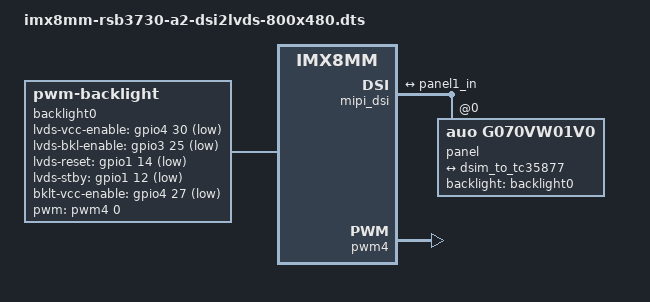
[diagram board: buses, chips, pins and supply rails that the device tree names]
/*
 * Copyright 2018 NXP
 *
 * This program is free software; you can redistribute it and/or
 * modify it under the terms of the GNU General Public License
 * as published by the Free Software Foundation; either version 2
 * of the License, or (at your option) any later version.
 *
 * This program is distributed in the hope that it will be useful,
 * but WITHOUT ANY WARRANTY; without even the implied warranty of
 * MERCHANTABILITY or FITNESS FOR A PARTICULAR PURPOSE.  See the
 * GNU General Public License for more details.
 */

#include "imx8mm-rsb3730-a2.dts"

/ {
	backlight0: backlight@0 {
                compatible = "pwm-backlight";
                pwms = <&pwm4 0 1000000 0>;
                brightness-levels = < 0  1  2  3  4  5  6  7  8  9
                             10 11 12 13 14 15 16 17 18 19
                             20 21 22 23 24 25 26 27 28 29
                             30 31 32 33 34 35 36 37 38 39
                             40 41 42 43 44 45 46 47 48 49
                             50 51 52 53 54 55 56 57 58 59
                             60 61 62 63 64 65 66 67 68 69
                             70 71 72 73 74 75 76 77 78 79
                             80 81 82 83 84 85 86 87 88 89
                             90 91 92 93 94 95 96 97 98 99
                            100>;
                default-brightness-level = <80>;
                default-enable = <0>;
        };
};

&lt9611uxc {
	status = "disabled";
	/delete-node/ ports;
};

&mipi_dsi {
	/delete-node/ port@1;

	panel@0 {
		compatible = "auo,g070vw01v0";
		reg = <0>;
		backlight=<&backlight0>;
		no-wakeup-init;
		panel-init-sequence = [
			29 00 06 3C 01 03 00 02 00
			29 00 06 14 01 02 00 00 00
			29 00 06 64 01 00 00 00 00
			29 00 06 68 01 00 00 00 00
			29 00 06 6C 01 00 00 00 00
			29 00 06 70 01 00 00 00 00
			29 00 06 34 01 1F 00 00 00
			29 00 06 10 02 1F 00 00 00
			29 00 06 04 01 01 00 00 00
			29 00 06 04 02 01 00 00 00
			29 00 06 50 04 20 01 F0 03
			29 00 06 54 04 06 00 32 00
			29 00 06 58 04 20 03 C8 00
			29 00 06 5C 04 04 00 04 00
			29 00 06 60 04 E0 01 14 00
			29 00 06 64 04 01 00 00 00
			29 01 06 A0 04 2D 80 44 00
			29 00 06 A0 04 2D 80 04 00
			29 00 06 04 05 04 00 00 00
			29 00 06 80 04 00 01 02 03
			29 00 06 84 04 04 07 05 08
			29 00 06 88 04 09 0A 0E 0F
			29 00 06 8C 04 0B 0C 0D 10
			29 00 06 90 04 16 17 11 12
			29 00 06 94 04 13 14 15 1B
			29 14 06 98 04 18 19 1A 06
			29 78 06 9C 04 31 00 00 00
		];
		panel-on-sequence = [
			05 78 01 11
			05 78 01 29
		];
		panel-off-sequence = [
			05 05 01 28
			05 78 01 10
		];

		port {
			panel1_in: endpoint {
				remote-endpoint = <&dsim_to_tc35877>;
			};
		};
	};

	port@1 {
		dsim_to_tc35877: endpoint {
			remote-endpoint = <&panel1_in>;
		};
	};
};

&pwm4 {
	status = "okay";
};

&backlight0 {
	pinctrl-names = "default";
	pinctrl-0 = <&pinctrl_bkl>;
	lvds-vcc-enable = <&gpio4 30 1>;
	lvds-bkl-enable = <&gpio3 25 1>;
	lvds-reset=<&gpio1 14 1>;
	lvds-stby=<&gpio1 12 1>;
	bklt-vcc-enable = <&gpio4 27 1>;
	status = "okay";
	lvds-bkl-delay-time = <150>;
	lvds-vcc-delay-time = <20>;
};

&iomuxc {
	pinctrl_bkl: bklgrp {
                fsl,pins = <
                        MX8MM_IOMUXC_SAI3_RXD_GPIO4_IO30	0x10		/* LCD0_VDD_EN */
                        MX8MM_IOMUXC_SAI2_MCLK_GPIO4_IO27	0x19		/* LCD0_BKLT_PWR_EN */
                        MX8MM_IOMUXC_SAI5_MCLK_GPIO3_IO25	0x19		/* LCD0_BKLT_EN */
                        MX8MM_IOMUXC_GPIO1_IO12_GPIO1_IO12	0x19		/* LVDS_STBY */
                        MX8MM_IOMUXC_GPIO1_IO14_GPIO1_IO14	0x19		/* LVDS_RESET */
                >;
        };
};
